# PIC32CM2532JH01032 register map
Vendor: Microchip Technology; Series: PIC32CMJH01; File version: 0
CPU: CM0+ r0p0, little endian, MPU, no FPU, VTOR, 2 interrupt priority bits, 32 interrupts
Registers are 32-bit, read-write, reset 0x0 unless marked. A register's access mark holds for its fields unless they carry their own. Offsets are from the block's base; [hi:lo] are bit positions; {n}, {i} and the like mark numbered series; 'fields as' and 'values as' point back to an identical list.

## CCL — Configurable Custom Logic
Base 0x42005800
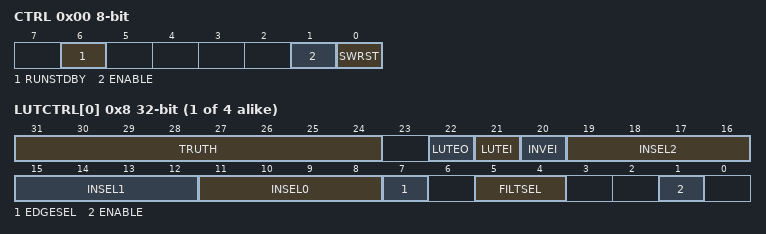
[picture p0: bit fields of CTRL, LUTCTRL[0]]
0x00 CTRL 8-bit — Control
  [6] RUNSTDBY — Run in Standby
    0=DISABLE (Generic clock is not required in standby sleep mode); 1=ENABLE (Generic clock is required in standby sleep mode)
  [1] ENABLE
    0=DISABLE (The peripheral is disabled); 1=ENABLE (The peripheral is enabled)
  [0] SWRST — Software Reset
    0=DISABLE (The peripheral is not reset); 1=ENABLE (The peripheral is reset)
{0x4+i} SEQCTRL[{i}] (i=0..1) 8-bit — SEQ Control x
  [3:0] SEQSEL — Sequential Selection
    0=DISABLE (Sequential logic is disabled); 1=DFF (D flip flop); 2=JK (JK flip flop); 3=LATCH (D latch); 4=RS (RS latch)
{0x8+4i} LUTCTRL[{i}] (i=0..3) — LUT Control x
  [31:24] TRUTH — Truth Value
  [22] LUTEO — LUT Event Output Enable
    0=DISABLE (LUT event output is disabled); 1=ENABLE (LUT event output is enabled)
  [21] LUTEI — LUT Event Input Enable
    0=DISABLE (LUT incoming event is disabled); 1=ENABLE (LUT incoming event is enabled)
  [20] INVEI — Inverted Event Input Enable
    0=NORMAL (Incoming event is not inverted); 1=INVERTED (Incoming event is inverted)
  [19:16] INSEL2 — Input Selection 2
    0=MASK (Masked input); 1=FEEDBACK (Feedback input source); 2=LINK (Linked LUT input source); 3=EVENT (Event input source); 4=IO (I/O pin input source); 5=AC (AC input source); 6=TC (TC input source); 7=ALTTC (Alternate TC input source); 8=TCC (TCC input source); 9=SERCOM (SERCOM input source); 10=ALT2TC (Second alternative TC input source); 11=ASYNCEVENT (Asynchronous event input source)
  [15:12] INSEL1 — Input Selection 1
    values as INSEL2
  [11:8] INSEL0 — Input Selection 0
    values as INSEL2
  [7] EDGESEL — Edge Selection
    0=DISABLE (Edge detector is disabled); 1=ENABLE (Edge detector is enabled)
  [5:4] FILTSEL — Filter Selection
    0=DISABLE (Filter disabled); 1=SYNCH (Synchronizer enabled); 2=FILTER (Filter enabled)
  [1] ENABLE — LUT Enable
    0=DISABLE (LUT block is disabled); 1=ENABLE (LUT block is enabled)

## DAC — Digital Analog Converter
Base 0x42005000
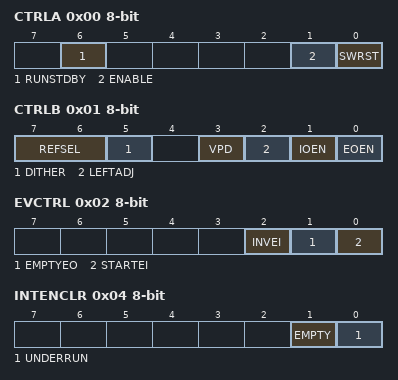
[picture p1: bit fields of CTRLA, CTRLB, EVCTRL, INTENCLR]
0x00 CTRLA 8-bit — Control A
  [6] RUNSTDBY — Run in Standby
  [1] ENABLE
  [0] SWRST — Software Reset
0x01 CTRLB 8-bit — Control B
  [7:6] REFSEL — Reference Selection
    0=INTREF (Internal Voltage Reference); 1=AVDD (Analog Voltage Supply); 2=VREFA (External Voltage Reference A (shared with ADC))
  [5] DITHER — Dither Enable
  [3] VPD — Voltage Pump Disable
  [2] LEFTADJ — Left Adjusted Data
  [1] IOEN — Internal Output Enable
  [0] EOEN — External Output Enable
0x02 EVCTRL 8-bit — Event Control
  [2] INVEI — Invert Event Input
  [1] EMPTYEO — Data Buffer Empty Event Output
  [0] STARTEI — Start Conversion Event Input
0x04 INTENCLR 8-bit write-1-clears — Interrupt Enable Clear
  [1] EMPTY — Data Buffer Empty Interrupt Enable
  [0] UNDERRUN — Underrun Interrupt Enable
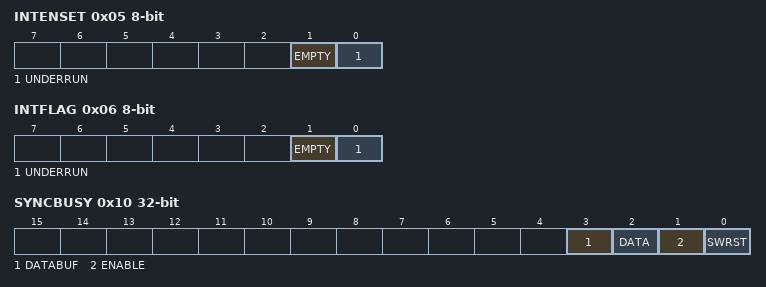
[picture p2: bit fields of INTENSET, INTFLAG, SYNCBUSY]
0x05 INTENSET 8-bit write-1-sets — Interrupt Enable Set
  fields as INTENCLR
0x06 INTFLAG 8-bit write-1-clears — Interrupt Flag Status and Clear
  [1] EMPTY — Data Buffer Empty
  [0] UNDERRUN
0x07 STATUS 8-bit ro
  [0] READY — DAC Ready
0x08 DATA 16-bit wo
  [15:0] DATA — Data value to be converted
0x0C DATABUF 16-bit wo — Data Buffer
0x10 SYNCBUSY ro — Synchronization Busy
  [3] DATABUF — Data Buffer
  [2] DATA
  [1] ENABLE — DAC Enable Status
  [0] SWRST — Software Reset
0x14 DBGCTRL 8-bit — Debug Control
  [0] DBGRUN — Debug Run

## DIVAS — Divide and Square Root Accelerator
Base 0x48000000
Same registers: DIVAS_IOBUS 0x60000200
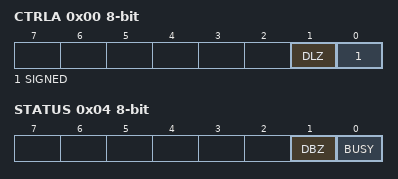
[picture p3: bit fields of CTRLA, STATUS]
0x00 CTRLA 8-bit — Control
  [1] DLZ — Disable Leading Zero Optimization
  [0] SIGNED
0x04 STATUS 8-bit
  [1] DBZ — Writing a one to this bit clears DBZ to zero
  [0] BUSY — DIVAS Accelerator Busy
0x08 DIVIDEND
0x0C DIVISOR
0x10 RESULT ro
0x14 REM ro — Remainder
0x18 SQRNUM — Square Root Input

## Notices in the file
Copyright (c) 2026 Microchip Technology Inc.
SPDX-License-Identifier: Apache-2.0
Licensed under the Apache License, Version 2.0 (the "License");
you may not use this file except in compliance with the License.
You may obtain a copy of the License at
http://www.apache.org/licenses/LICENSE-2.0
Unless required by applicable law or agreed to in writing, software
distributed under the License is distributed on an "AS IS" BASIS,
WITHOUT WARRANTIES OR CONDITIONS OF ANY KIND, either express or implied.
See the License for the specific language governing permissions and
limitations under the License.
